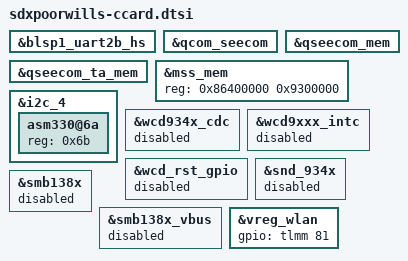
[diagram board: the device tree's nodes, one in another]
/* Copyright (c) 2019, The Linux Foundation. All rights reserved.
 *
 * This program is free software; you can redistribute it and/or modify
 * it under the terms of the GNU General Public License version 2 and
 * only version 2 as published by the Free Software Foundation.
 *
 * This program is distributed in the hope that it will be useful,
 * but WITHOUT ANY WARRANTY; without even the implied warranty of
 * MERCHANTABILITY or FITNESS FOR A PARTICULAR PURPOSE.  See the
 * GNU General Public License for more details.
 */

#include "sdxpoorwills-ttp.dtsi"
#include "sdxpoorwills-v2.dtsi"

&blsp1_uart2b_hs {
	status = "okay";
};

&qcom_seecom {
	status = "okay";
};

&qseecom_mem {
	status = "okay";
};

&qseecom_ta_mem {
	status = "okay";
};

&blsp1_uart2b_hs {
	status = "okay";
};

&mss_mem {
	reg = <0x86400000 0x9300000>;
};

&i2c_4 {
	asm330@6a {
		reg = <0x6b>;
	};
};

&wcd934x_cdc {
	status = "disabled";
};

&wcd9xxx_intc {
	status = "disabled";
};

&wcd_rst_gpio {
	status = "disabled";
};

&snd_934x {
	status = "disabled";
};

&smb138x {
	status = "disabled";
};

&smb138x_vbus {
	status = "disabled";
};

&vreg_wlan {
	gpio = <&tlmm 81 GPIO_ACTIVE_HIGH>;
};
